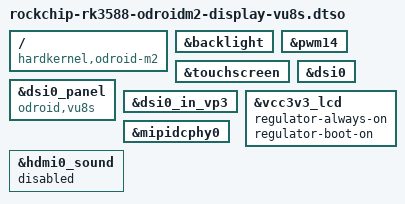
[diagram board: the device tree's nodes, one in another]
/dts-v1/;
/plugin/;

/ {
	compatible = "hardkernel,odroid-m2", "rockchip,rk3588s";
};

&backlight {
	status = "okay";
};

&pwm14 {
	status = "okay";
};

&touchscreen {
	status = "okay";
};

&dsi0 {
	status = "okay";
};

&dsi0_panel {
	status = "okay";
	compatible = "odroid,vu8s";
};

&dsi0_in_vp3 {
	status = "okay";
};

&vcc3v3_lcd {
	regulator-always-on;
	regulator-boot-on;
};

&mipidcphy0 {
	status = "okay";
};

&hdmi0_sound {
	status = "disabled";
};
